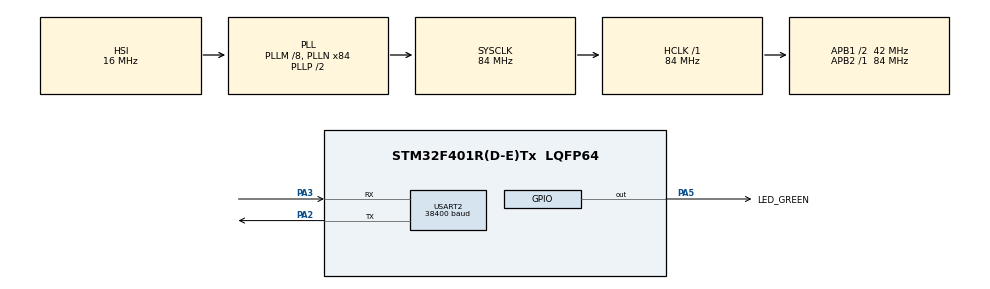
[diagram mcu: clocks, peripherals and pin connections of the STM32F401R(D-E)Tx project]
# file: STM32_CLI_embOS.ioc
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Dma.Request0=USART2_RX
Dma.Request1=USART2_TX
Dma.USART2_RX.0.Direction=DMA_PERIPH_TO_MEMORY
Dma.USART2_RX.0.FIFOMode=DMA_FIFOMODE_DISABLE
Dma.USART2_RX.0.Instance=DMA1_Stream5
Dma.USART2_RX.0.MemDataAlignment=DMA_MDATAALIGN_BYTE
Dma.USART2_RX.0.MemInc=DMA_MINC_ENABLE
Dma.USART2_RX.0.Mode=DMA_CIRCULAR
Dma.USART2_RX.0.PeriphDataAlignment=DMA_PDATAALIGN_BYTE
Dma.USART2_RX.0.PeriphInc=DMA_PINC_DISABLE
Dma.USART2_RX.0.Priority=DMA_PRIORITY_LOW
Dma.USART2_TX.1.Direction=DMA_MEMORY_TO_PERIPH
Dma.USART2_TX.1.FIFOMode=DMA_FIFOMODE_DISABLE
Dma.USART2_TX.1.Instance=DMA1_Stream6
Dma.USART2_TX.1.MemDataAlignment=DMA_MDATAALIGN_BYTE
Dma.USART2_TX.1.MemInc=DMA_MINC_ENABLE
Dma.USART2_TX.1.Mode=DMA_NORMAL
Dma.USART2_TX.1.PeriphDataAlignment=DMA_PDATAALIGN_BYTE
Dma.USART2_TX.1.PeriphInc=DMA_PINC_DISABLE
Dma.USART2_TX.1.Priority=DMA_PRIORITY_LOW
Mcu.Family=STM32F4
Mcu.Name=STM32F401R(D-E)Tx
Mcu.Package=LQFP64
NVIC.DMA1_Stream5_IRQn=true\:10\:0\:true\:false\:true\:false\:true
NVIC.DMA1_Stream6_IRQn=true\:10\:0\:true\:false\:true\:false\:true
NVIC.PriorityGroup=NVIC_PRIORITYGROUP_4
NVIC.USART2_IRQn=true\:10\:0\:true\:false\:true\:true\:true
PA13.Mode=Serial_Wire
PA13.Signal=SYS_JTMS-SWDIO
PA14.Mode=Serial_Wire
PA14.Signal=SYS_JTCK-SWCLK
PA2.Mode=Asynchronous
PA2.Signal=USART2_TX
PA3.Mode=Asynchronous
PA3.Signal=USART2_RX
PA5.GPIO_Label=LED_GREEN
PA5.PinState=GPIO_PIN_SET
PA5.Signal=GPIO_Output
ProjectManager.HeapSize=0x200
ProjectManager.StackSize=0x400
ProjectManager.TargetToolchain=STM32CubeIDE
RCC.48MHZClocksFreq_Value=42000000
RCC.AHBFreq_Value=84000000
RCC.APB1CLKDivider=RCC_HCLK_DIV2
RCC.APB1Freq_Value=42000000
RCC.APB1TimFreq_Value=84000000
RCC.APB2Freq_Value=84000000
RCC.APB2TimFreq_Value=84000000
RCC.CortexFreq_Value=84000000
RCC.HCLKFreq_Value=84000000
RCC.HSE_VALUE=25000000
RCC.HSI_VALUE=16000000
RCC.LSE_VALUE=32768
RCC.PLLM=8
RCC.PLLN=84
RCC.SYSCLKFreq_VALUE=84000000
RCC.SYSCLKSource=RCC_SYSCLKSOURCE_PLLCLK
RCC.VCOOutputFreq_Value=168000000
USART2.BaudRate=38400
USART2.VirtualMode=VM_ASYNC
board=custom

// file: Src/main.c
/* USER CODE BEGIN Header */
/**
  ******************************************************************************
  * @file           : main.c
  * @brief          : Main program body
  ******************************************************************************
  * @attention
  *
  * <h2><center>&copy; Copyright (c) 2019 STMicroelectronics.
  * All rights reserved.</center></h2>
  *
  * This software component is licensed by ST under BSD 3-Clause license,
  * the "License"; You may not use this file except in compliance with the
  * License. You may obtain a copy of the License at:
  *                        opensource.org/licenses/BSD-3-Clause
  *
  ******************************************************************************
  */
/* USER CODE END Header */

#include "main.h"
#include "dma.h"
#include "usart.h"
#include "gpio.h"

/* USER CODE BEGIN Includes */
#include "cli_uart_interface.h"
#include "RTOS.h"
/* USER CODE END Includes */

/* USER CODE BEGIN PV */
static OS_STACKPTR int Blinky_Task_Stack[128];  // Task stacks
static OS_TASK         Blinky_Task_TCB;
/* USER CODE END PV */

void SystemClock_Config(void);

/* USER CODE BEGIN 0 */
static void Blinky_Task(void)
    {
    while (1)
	{
	HAL_GPIO_TogglePin(LED_GREEN_GPIO_Port, LED_GREEN_Pin);
	OS_TASK_Delay(500);
	}
    }
/* USER CODE END 0 */

int main(void)
{

  /* MCU Configuration--------------------------------------------------------*/

  /* Reset of all peripherals, Initializes the Flash interface and the Systick. */
  HAL_Init();

  /* Configure the system clock */
  SystemClock_Config();

  /* Initialize all configured peripherals */
  MX_GPIO_Init();
  MX_DMA_Init();
  MX_USART2_UART_Init();
  /* USER CODE BEGIN 2 */

  __disable_irq();
  HAL_NVIC_SetPriority(SysTick_IRQn, 15, 0U);

  OS_Init();    // Initialize embOS
  OS_InitHW();  // Initialize required hardware
  OS_TASK_CREATE(&Blinky_Task_TCB, "Blinky_Task", 100, Blinky_Task, Blinky_Task_Stack);
  CLI_UART_Thread_Add();
  OS_Start();   // Start embOS

  /* USER CODE END 2 */

  /* Infinite loop */
  while (1)
  {

  }
}

void SystemClock_Config(void)
{
  RCC_OscInitTypeDef RCC_OscInitStruct = {0};
  RCC_ClkInitTypeDef RCC_ClkInitStruct = {0};

  /** Configure the main internal regulator output voltage
  */
  __HAL_RCC_PWR_CLK_ENABLE();
  __HAL_PWR_VOLTAGESCALING_CONFIG(PWR_REGULATOR_VOLTAGE_SCALE2);
  /** Initializes the CPU, AHB and APB busses clocks
  */
  RCC_OscInitStruct.OscillatorType = RCC_OSCILLATORTYPE_HSI;
  RCC_OscInitStruct.HSIState = RCC_HSI_ON;
  RCC_OscInitStruct.HSICalibrationValue = RCC_HSICALIBRATION_DEFAULT;
  RCC_OscInitStruct.PLL.PLLState = RCC_PLL_ON;
  RCC_OscInitStruct.PLL.PLLSource = RCC_PLLSOURCE_HSI;
  RCC_OscInitStruct.PLL.PLLM = 8;
  RCC_OscInitStruct.PLL.PLLN = 84;
  RCC_OscInitStruct.PLL.PLLP = RCC_PLLP_DIV2;
  RCC_OscInitStruct.PLL.PLLQ = 4;
  if (HAL_RCC_OscConfig(&RCC_OscInitStruct) != HAL_OK)
  {
    Error_Handler();
  }
  /** Initializes the CPU, AHB and APB busses clocks
  */
  RCC_ClkInitStruct.ClockType = RCC_CLOCKTYPE_HCLK|RCC_CLOCKTYPE_SYSCLK
                              |RCC_CLOCKTYPE_PCLK1|RCC_CLOCKTYPE_PCLK2;
  RCC_ClkInitStruct.SYSCLKSource = RCC_SYSCLKSOURCE_PLLCLK;
  RCC_ClkInitStruct.AHBCLKDivider = RCC_SYSCLK_DIV1;
  RCC_ClkInitStruct.APB1CLKDivider = RCC_HCLK_DIV2;
  RCC_ClkInitStruct.APB2CLKDivider = RCC_HCLK_DIV1;

  if (HAL_RCC_ClockConfig(&RCC_ClkInitStruct, FLASH_LATENCY_2) != HAL_OK)
  {
    Error_Handler();
  }
}

void Error_Handler(void)
{
}

/************************ (C) COPYRIGHT STMicroelectronics *****END OF FILE****/
